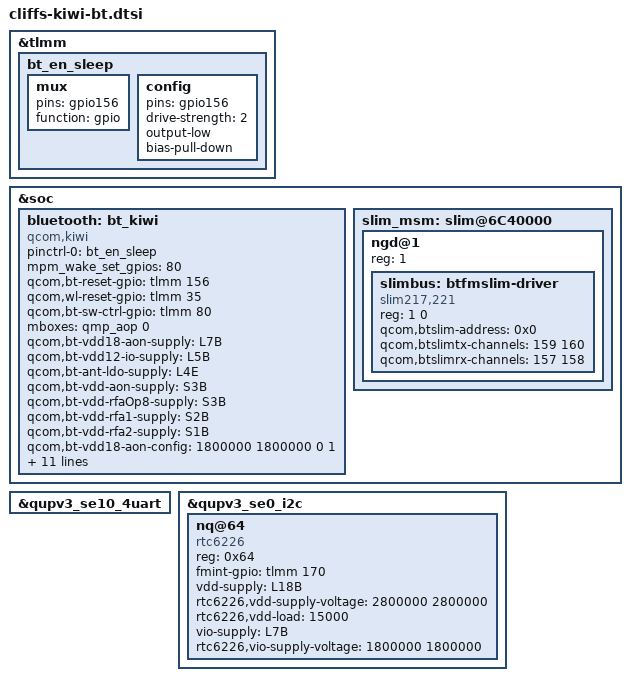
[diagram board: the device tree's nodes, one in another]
#include <dt-bindings/interconnect/qcom,cliffs.h>

&tlmm {
	bt_en_sleep: bt_en_sleep {
		mux {
			pins = "gpio156";
			function = "gpio";
		};

		config {
			pins = "gpio156";
			drive-strength = <2>;
			output-low;
			bias-pull-down;
		};
	};
};

&soc {
	bluetooth: bt_kiwi {
			compatible = "qcom,kiwi";
			pinctrl-names = "bt_en_sleep";
			pinctrl-0 = <&bt_en_sleep>;
			/* List of GPIOs to be setup for interrupt wakeup capable*/
			mpm_wake_set_gpios = <80>;
			qcom,bt-reset-gpio = <&tlmm 156 0>; /* BT_EN */
			qcom,wl-reset-gpio = <&tlmm 35 0>; /* WL_EN */
			qcom,bt-sw-ctrl-gpio = <&tlmm 80 0>; /* SW_CTRL */
			mboxes = <&qmp_aop 0>;

			qcom,bt-vdd18-aon-supply  = <&L7B>; /* BT VDD1.8 AON */
			qcom,bt-vdd12-io-supply   = <&L5B>;  /* BT VDD1.2V IO */
			qcom,bt-ant-ldo-supply    = <&L4E>;  /* BT ANT - AV91C_VDD */
			qcom,bt-vdd-aon-supply    = <&S3B>;  /* BT AON LDO*/
			qcom,bt-vdd-rfaOp8-supply = <&S3B>;  /* BT RFAOp8 CMN LDO*/
			qcom,bt-vdd-rfa1-supply   = <&S2B>;  /* BT RFA1.2 LDO */
			qcom,bt-vdd-rfa2-supply   = <&S1B>;  /* BT RFA1.8 LDO */

			qcom,bt-vdd18-aon-config  = <1800000 1800000 0 1>;
			qcom,bt-vdd12-io-config   = <1200000 1200000 0 1>;
			qcom,bt-ant-ldo-config    = <1800000 2000000 0 1>;
			qcom,bt-vdd-aon-config    = <968000 1040000 0 1>;
			qcom,bt-vdd-rfaOp8-config = <968000 1040000 0 1>;
			qcom,bt-vdd-rfa1-config   = <1256000 1408000 0 1>;
			qcom,bt-vdd-rfa2-config   = <1856000 2040000 0 1>;

			qcom,pdc_init_table =
				"{class: wlan_pdc, ss: rf, res: l5b.m, enable: 0}",
				"{class: wlan_pdc, ss: rf, res: s3b.v, upval: 976}",
				"{class: wlan_pdc, ss: rf, res: s1b.v, upval: 1864}",
				"{class: wlan_pdc, ss: rf, res: s2b.v, upval: 1316}";
	};

	slim_msm: slim@6C40000 {
		status =  "ok";
		ngd@1 {
			reg = <1>;
			#address-cells = <1>;
			#size-cells = <1>;
			//slimbus child nodes
			slimbus: btfmslim-driver {
				compatible = "slim217,221";
				reg = <1 0>;
				qcom,btslim-address  = <0x0>; /* BT SLIM EP address*/
				qcom,btslimtx-channels = <159 160>; /* slimbus FM_Tx, SCO_Tx channels */
				qcom,btslimrx-channels = <157 158>; /* slimbus SCO_A2DP_Rx A2DP_Rx */
			};
		};
	};
};

//uart instance
&qupv3_se10_4uart {
	status = "ok";
};

// FM changes
&qupv3_se0_i2c {
	status = "ok";
	nq@64 {
		compatible = "rtc6226";
		reg = <0x64>;
		fmint-gpio = <&tlmm 170 0>;
		vdd-supply = <&L18B>;
		rtc6226,vdd-supply-voltage = <2800000 2800000>;
		rtc6226,vdd-load = <15000>;
		vio-supply = <&L7B>;
		rtc6226,vio-supply-voltage = <1800000 1800000>;
	};
};
